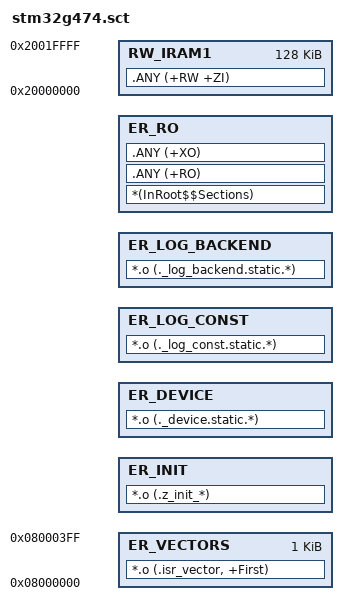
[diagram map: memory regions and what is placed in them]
; SPDX-License-Identifier: BSD-3-Clause
;
; STM32G474 scatter file (armlink, armclang AC6).
;
; All init entries land in one ER_INIT region; their order is driven by the
; build-generated table in lib/utils/init_order.inc (consumed by
; lib/utils/init_runner.c), not by linker section ordering. armlink does not
; sort input sections, so a single KEEP-all region plus a sorted table replaces
; the previous per-level / per-priority regions.
;
; Flash: 512 KB (0x08000000..0x08080000). RAM: 128 KB (0x20000000..0x20020000).

LR_IROM1 0x08000000 0x00080000 {
  ER_VECTORS 0x08000000 0x00000400 {
    *.o (.isr_vector, +First)
  }

  ER_INIT +0 {
    *.o (.z_init_*)
  }

  ER_DEVICE +0 {
    *.o (._device.static.*)
  }

  ER_LOG_CONST +0 {
    *.o (._log_const.static.*)
  }

  ER_LOG_BACKEND +0 {
    *.o (._log_backend.static.*)
  }

  ER_RO +0 {
    *(InRoot$$Sections)
    .ANY (+RO)
    .ANY (+XO)
  }

  RW_IRAM1 0x20000000 0x00020000 {
    .ANY (+RW +ZI)
  }
}
